# 602 register map
Vendor: bouffalolab; Series: WiFi BT
CPU: 602, little endian
Registers are 32-bit, read-write, reset 0x0 unless marked. A register's access mark holds for its fields unless they carry their own. Offsets are from the block's base; [hi:lo] are bit positions; {n}, {i} and the like mark numbered series.

## glb
Base 0x40000000
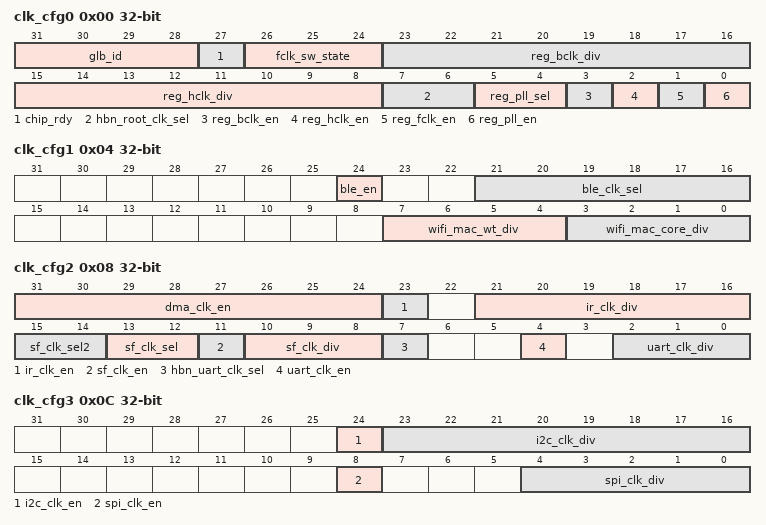
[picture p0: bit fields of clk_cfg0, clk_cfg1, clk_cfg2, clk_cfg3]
0x00 clk_cfg0
  [31:28] glb_id, [27] chip_rdy, [26:24] fclk_sw_state, [23:16] reg_bclk_div, [15:8] reg_hclk_div, [7:6] hbn_root_clk_sel, [5:4] reg_pll_sel, [3] reg_bclk_en, [2] reg_hclk_en, [1] reg_fclk_en, [0] reg_pll_en
0x04 clk_cfg1
  [24] ble_en, [21:16] ble_clk_sel, [7:4] wifi_mac_wt_div, [3:0] wifi_mac_core_div
0x08 clk_cfg2
  [31:24] dma_clk_en, [23] ir_clk_en, [21:16] ir_clk_div, [15:14] sf_clk_sel2, [13:12] sf_clk_sel, [11] sf_clk_en, [10:8] sf_clk_div, [7] hbn_uart_clk_sel, [4] uart_clk_en, [2:0] uart_clk_div
0x0C clk_cfg3
  [24] i2c_clk_en, [23:16] i2c_clk_div, [8] spi_clk_en, [4:0] spi_clk_div
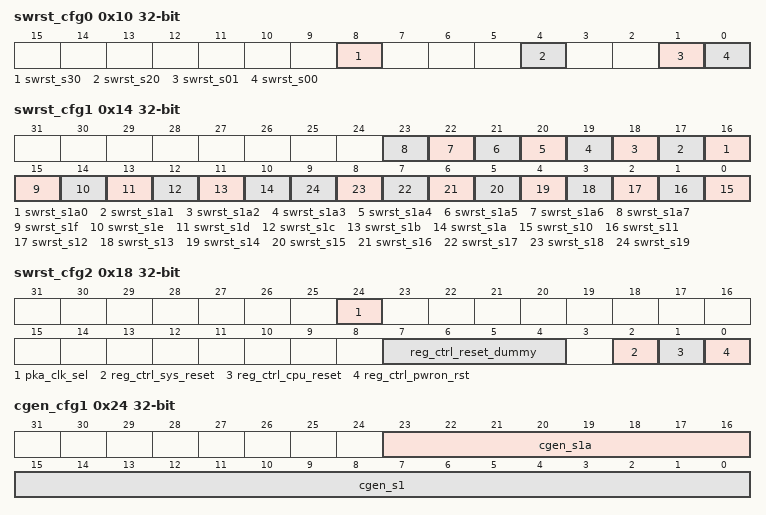
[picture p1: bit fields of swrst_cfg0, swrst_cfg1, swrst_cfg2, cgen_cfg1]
0x10 swrst_cfg0
  [8] swrst_s30, [4] swrst_s20, [1] swrst_s01, [0] swrst_s00
0x14 swrst_cfg1
  [n+16] swrst_s1a{n} (n=0..7), [15] swrst_s1f, [14] swrst_s1e, [13] swrst_s1d, [12] swrst_s1c, [11] swrst_s1b, [10] swrst_s1a, [n-10] swrst_s{n} (n=10..19)
0x18 swrst_cfg2
  [24] pka_clk_sel, [7:4] reg_ctrl_reset_dummy, [2] reg_ctrl_sys_reset, [1] reg_ctrl_cpu_reset, [0] reg_ctrl_pwron_rst
0x1C swrst_cfg3
0x20 cgen_cfg0
  [7:0] cgen_m
0x24 cgen_cfg1
  [23:16] cgen_s1a, [15:0] cgen_s1
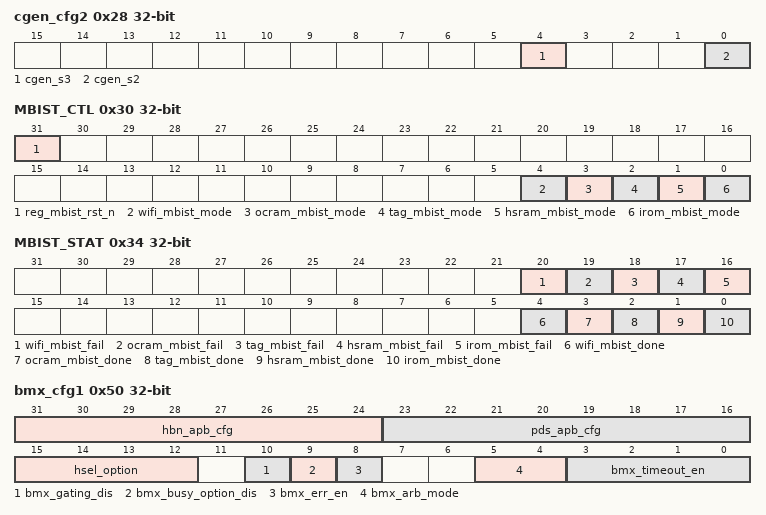
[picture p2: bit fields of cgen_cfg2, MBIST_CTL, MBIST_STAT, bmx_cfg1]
0x28 cgen_cfg2
  [4] cgen_s3, [0] cgen_s2
0x2C cgen_cfg3
0x30 MBIST_CTL
  [31] reg_mbist_rst_n, [4] wifi_mbist_mode, [3] ocram_mbist_mode, [2] tag_mbist_mode, [1] hsram_mbist_mode, [0] irom_mbist_mode
0x34 MBIST_STAT
  [20] wifi_mbist_fail, [19] ocram_mbist_fail, [18] tag_mbist_fail, [17] hsram_mbist_fail, [16] irom_mbist_fail, [4] wifi_mbist_done, [3] ocram_mbist_done, [2] tag_mbist_done, [1] hsram_mbist_done, [0] irom_mbist_done
0x50 bmx_cfg1
  [31:24] hbn_apb_cfg, [23:16] pds_apb_cfg, [15:12] hsel_option, [10] bmx_gating_dis, [9] bmx_busy_option_dis, [8] bmx_err_en, [5:4] bmx_arb_mode, [3:0] bmx_timeout_en
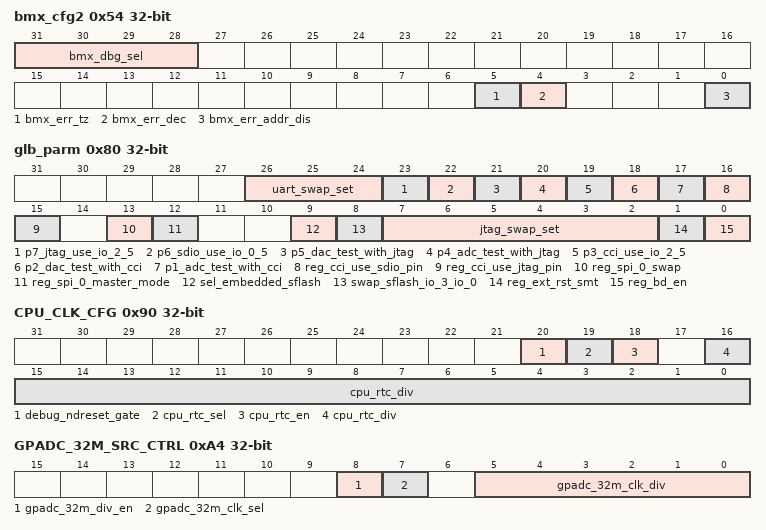
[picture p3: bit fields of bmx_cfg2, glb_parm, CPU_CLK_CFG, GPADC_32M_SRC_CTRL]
0x54 bmx_cfg2
  [31:28] bmx_dbg_sel, [5] bmx_err_tz, [4] bmx_err_dec, [0] bmx_err_addr_dis
0x58 bmx_err_addr
0x5C bmx_dbg_out
{0x60+4i} rsv{i} (i=0..3)
0x70 sram_ret
  [31:0] reg_sram_ret
0x74 sram_slp
  [31:0] reg_sram_slp
0x78 sram_parm
  [31:0] reg_sram_parm
0x7C seam_misc
  [3:0] em_sel
0x80 glb_parm
  [26:24] uart_swap_set, [23] p7_jtag_use_io_2_5, [22] p6_sdio_use_io_0_5, [21] p5_dac_test_with_jtag, [20] p4_adc_test_with_jtag, [19] p3_cci_use_io_2_5, [18] p2_dac_test_with_cci, [17] p1_adc_test_with_cci, [16] reg_cci_use_sdio_pin, [15] reg_cci_use_jtag_pin, [13] reg_spi_0_swap, [12] reg_spi_0_master_mode, [9] sel_embedded_sflash, [8] swap_sflash_io_3_io_0, [7:2] jtag_swap_set, [1] reg_ext_rst_smt, [0] reg_bd_en
0x90 CPU_CLK_CFG
  [20] debug_ndreset_gate, [19] cpu_rtc_sel, [18] cpu_rtc_en, [16:0] cpu_rtc_div
0xA4 GPADC_32M_SRC_CTRL
  [8] gpadc_32m_div_en, [7] gpadc_32m_clk_sel, [5:0] gpadc_32m_clk_div
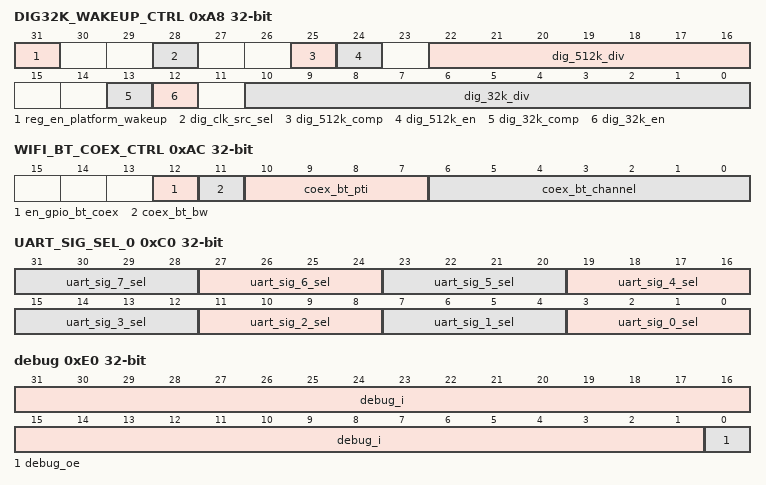
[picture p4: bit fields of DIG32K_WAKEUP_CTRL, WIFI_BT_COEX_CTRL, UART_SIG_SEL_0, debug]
0xA8 DIG32K_WAKEUP_CTRL
  [31] reg_en_platform_wakeup, [28] dig_clk_src_sel, [25] dig_512k_comp, [24] dig_512k_en, [22:16] dig_512k_div, [13] dig_32k_comp, [12] dig_32k_en, [10:0] dig_32k_div
0xAC WIFI_BT_COEX_CTRL
  [12] en_gpio_bt_coex, [11] coex_bt_bw, [10:7] coex_bt_pti, [6:0] coex_bt_channel
0xC0 UART_SIG_SEL_0
  [4n+3:4n] uart_sig_{n}_sel (n=0..7)
0xD0 DBG_SEL_LL
  [31:0] reg_dbg_ll_ctrl
0xD4 DBG_SEL_LH
  [31:0] reg_dbg_lh_ctrl
0xD8 DBG_SEL_HL
  [31:0] reg_dbg_hl_ctrl
0xDC DBG_SEL_HH
  [31:0] reg_dbg_hh_ctrl
0xE0 debug
  [31:1] debug_i, [0] debug_oe
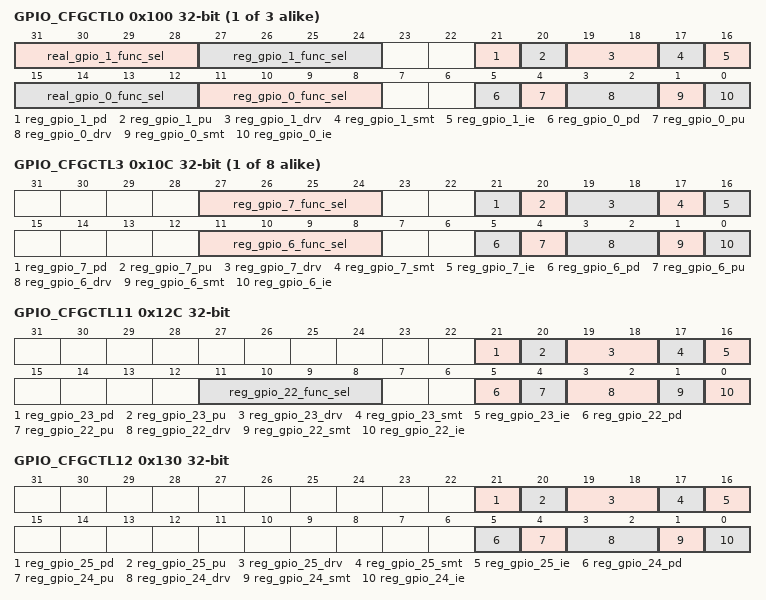
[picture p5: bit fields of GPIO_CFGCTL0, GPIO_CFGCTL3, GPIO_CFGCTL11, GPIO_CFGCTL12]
{0x100+4i} GPIO_CFGCTL{i} (i=0..2)
  [31:28] real_gpio_{2i+1}_func_sel, [27:24] reg_gpio_{2i+1}_func_sel, [21] reg_gpio_{2i+1}_pd, [20] reg_gpio_{2i+1}_pu, [19:18] reg_gpio_{2i+1}_drv, [17] reg_gpio_{2i+1}_smt, [16] reg_gpio_{2i+1}_ie, [15:12] real_gpio_{2i}_func_sel, [11:8] reg_gpio_{2i}_func_sel, [5] reg_gpio_{2i}_pd, [4] reg_gpio_{2i}_pu, [3:2] reg_gpio_{2i}_drv, [1] reg_gpio_{2i}_smt, [0] reg_gpio_{2i}_ie
{0x100+4i} GPIO_CFGCTL{i} (i=3..10)
  [27:24] reg_gpio_{2i+1}_func_sel, [21] reg_gpio_{2i+1}_pd, [20] reg_gpio_{2i+1}_pu, [19:18] reg_gpio_{2i+1}_drv, [17] reg_gpio_{2i+1}_smt, [16] reg_gpio_{2i+1}_ie, [11:8] reg_gpio_{2i}_func_sel, [5] reg_gpio_{2i}_pd, [4] reg_gpio_{2i}_pu, [3:2] reg_gpio_{2i}_drv, [1] reg_gpio_{2i}_smt, [0] reg_gpio_{2i}_ie
0x12C GPIO_CFGCTL11
  [21] reg_gpio_23_pd, [20] reg_gpio_23_pu, [19:18] reg_gpio_23_drv, [17] reg_gpio_23_smt, [16] reg_gpio_23_ie, [11:8] reg_gpio_22_func_sel, [5] reg_gpio_22_pd, [4] reg_gpio_22_pu, [3:2] reg_gpio_22_drv, [1] reg_gpio_22_smt, [0] reg_gpio_22_ie
0x130 GPIO_CFGCTL12
  [21] reg_gpio_25_pd, [20] reg_gpio_25_pu, [19:18] reg_gpio_25_drv, [17] reg_gpio_25_smt, [16] reg_gpio_25_ie, [5] reg_gpio_24_pd, [4] reg_gpio_24_pu, [3:2] reg_gpio_24_drv, [1] reg_gpio_24_smt, [0] reg_gpio_24_ie
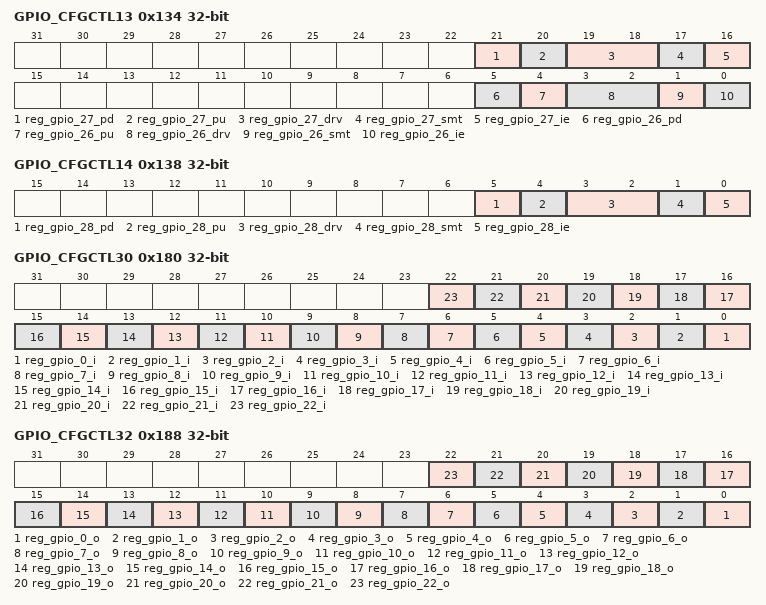
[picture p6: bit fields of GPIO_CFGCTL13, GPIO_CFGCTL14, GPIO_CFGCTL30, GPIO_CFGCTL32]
0x134 GPIO_CFGCTL13
  [21] reg_gpio_27_pd, [20] reg_gpio_27_pu, [19:18] reg_gpio_27_drv, [17] reg_gpio_27_smt, [16] reg_gpio_27_ie, [5] reg_gpio_26_pd, [4] reg_gpio_26_pu, [3:2] reg_gpio_26_drv, [1] reg_gpio_26_smt, [0] reg_gpio_26_ie
0x138 GPIO_CFGCTL14
  [5] reg_gpio_28_pd, [4] reg_gpio_28_pu, [3:2] reg_gpio_28_drv, [1] reg_gpio_28_smt, [0] reg_gpio_28_ie
0x180 GPIO_CFGCTL30
  [n] reg_gpio_{n}_i (n=0..22)
0x184 GPIO_CFGCTL31
0x188 GPIO_CFGCTL32
  [n] reg_gpio_{n}_o (n=0..22)
0x18C GPIO_CFGCTL33
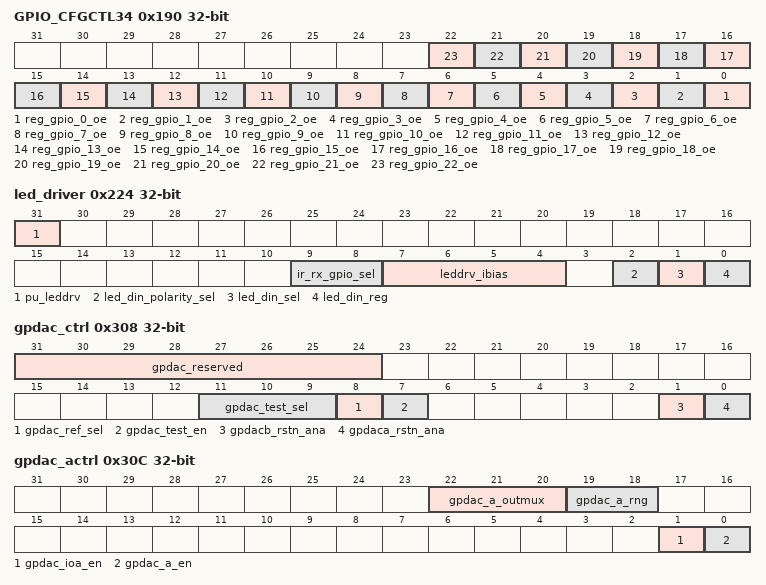
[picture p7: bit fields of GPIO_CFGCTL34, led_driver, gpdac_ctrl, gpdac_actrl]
0x190 GPIO_CFGCTL34
  [n] reg_gpio_{n}_oe (n=0..22)
0x194 GPIO_CFGCTL35
0x1A0 GPIO_INT_MASK1
  [31:0] reg_gpio_int_mask1
0x1A8 GPIO_INT_STAT1
0x1B0 GPIO_INT_CLR1
  [31:0] reg_gpio_int_clr1
{0x1BC+4i} GPIO_INT_MODE_SET{i} (i=1..3)
  [31:0] reg_gpio_int_mode_set{i}
0x224 led_driver
  [31] pu_leddrv, [9:8] ir_rx_gpio_sel, [7:4] leddrv_ibias, [2] led_din_polarity_sel, [1] led_din_sel, [0] led_din_reg
0x308 gpdac_ctrl
  [31:24] gpdac_reserved, [11:9] gpdac_test_sel, [8] gpdac_ref_sel, [7] gpdac_test_en, [1] gpdacb_rstn_ana, [0] gpdaca_rstn_ana
0x30C gpdac_actrl
  [22:20] gpdac_a_outmux, [19:18] gpdac_a_rng, [1] gpdac_ioa_en, [0] gpdac_a_en
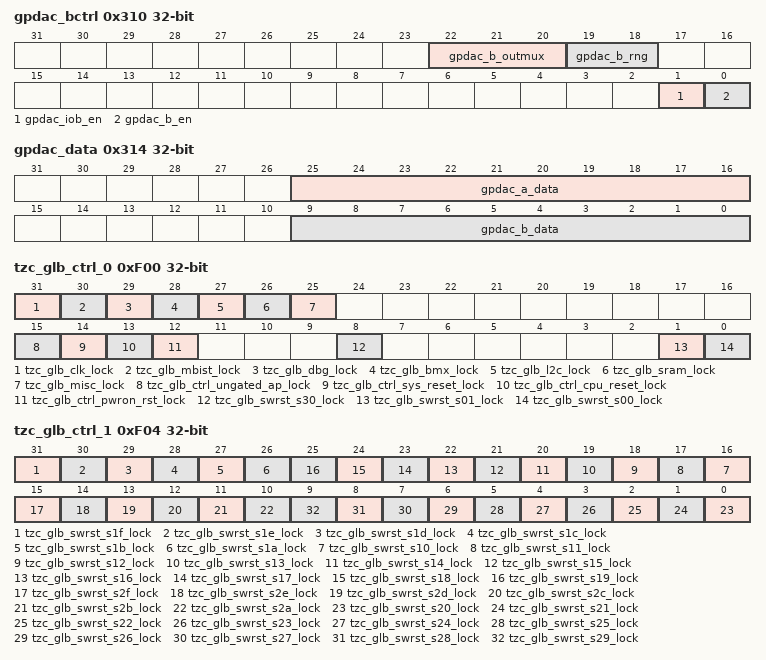
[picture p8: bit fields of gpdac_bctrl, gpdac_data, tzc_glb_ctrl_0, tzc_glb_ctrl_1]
0x310 gpdac_bctrl
  [22:20] gpdac_b_outmux, [19:18] gpdac_b_rng, [1] gpdac_iob_en, [0] gpdac_b_en
0x314 gpdac_data
  [25:16] gpdac_a_data, [9:0] gpdac_b_data
0xF00 tzc_glb_ctrl_0
  [31] tzc_glb_clk_lock, [30] tzc_glb_mbist_lock, [29] tzc_glb_dbg_lock, [28] tzc_glb_bmx_lock, [27] tzc_glb_l2c_lock, [26] tzc_glb_sram_lock, [25] tzc_glb_misc_lock, [15] tzc_glb_ctrl_ungated_ap_lock, [14] tzc_glb_ctrl_sys_reset_lock, [13] tzc_glb_ctrl_cpu_reset_lock, [12] tzc_glb_ctrl_pwron_rst_lock, [8] tzc_glb_swrst_s30_lock, [1] tzc_glb_swrst_s01_lock, [0] tzc_glb_swrst_s00_lock
0xF04 tzc_glb_ctrl_1
  [31] tzc_glb_swrst_s1f_lock, [30] tzc_glb_swrst_s1e_lock, [29] tzc_glb_swrst_s1d_lock, [28] tzc_glb_swrst_s1c_lock, [27] tzc_glb_swrst_s1b_lock, [26] tzc_glb_swrst_s1a_lock, [n+6] tzc_glb_swrst_s{n}_lock (n=10..19), [15] tzc_glb_swrst_s2f_lock, [14] tzc_glb_swrst_s2e_lock, [13] tzc_glb_swrst_s2d_lock, [12] tzc_glb_swrst_s2c_lock, [11] tzc_glb_swrst_s2b_lock, [10] tzc_glb_swrst_s2a_lock, [n-20] tzc_glb_swrst_s{n}_lock (n=20..29)
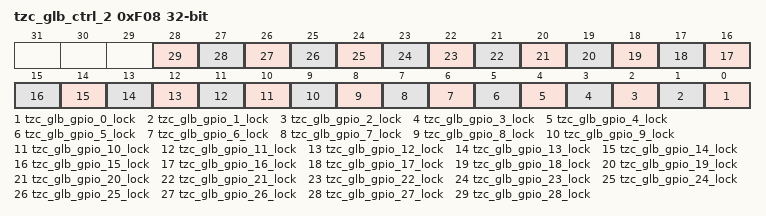
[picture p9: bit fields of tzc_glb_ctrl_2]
0xF08 tzc_glb_ctrl_2
  [n] tzc_glb_gpio_{n}_lock (n=0..28)
0xF0C tzc_glb_ctrl_3
